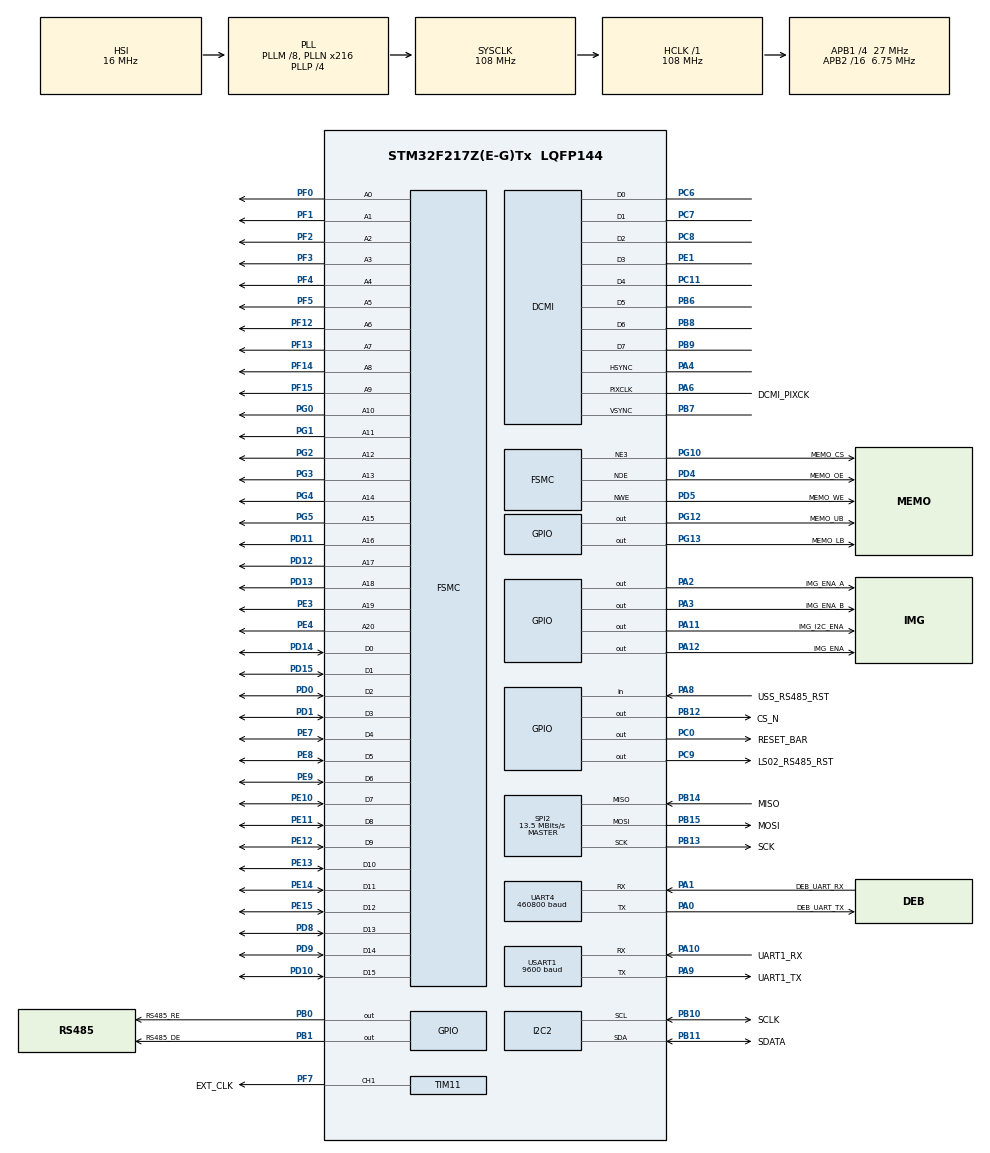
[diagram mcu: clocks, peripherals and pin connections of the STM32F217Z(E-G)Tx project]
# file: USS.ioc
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ADC1.Channel-1\#ChannelRegularConversion=ADC_CHANNEL_TEMPSENSOR
ADC1.Channel-2\#ChannelRegularConversion=ADC_CHANNEL_VREFINT
ADC1.InjNumberOfConversion=0
ADC1.NbrOfConversion=2
ADC1.NbrOfConversionFlag=1
ADC1.Rank-1\#ChannelRegularConversion=1
ADC1.Rank-2\#ChannelRegularConversion=2
ADC1.SamplingTime-1\#ChannelRegularConversion=ADC_SAMPLETIME_144CYCLES
ADC1.SamplingTime-2\#ChannelRegularConversion=ADC_SAMPLETIME_144CYCLES
ADC1.ScanConvMode=ENABLE
ADC1.master=1
DCMI.HSPolarity=DCMI_HSPOLARITY_LOW
DCMI.JPEGMode=DCMI_JPEG_DISABLE
DCMI.PCKPolarity=DCMI_PCKPOLARITY_RISING
DCMI.VSPolarity=DCMI_VSPOLARITY_LOW
Dma.DCMI.0.Direction=DMA_PERIPH_TO_MEMORY
Dma.DCMI.0.FIFOMode=DMA_FIFOMODE_ENABLE
Dma.DCMI.0.FIFOThreshold=DMA_FIFO_THRESHOLD_FULL
Dma.DCMI.0.Instance=DMA2_Stream1
Dma.DCMI.0.MemBurst=DMA_MBURST_INC4
Dma.DCMI.0.MemDataAlignment=DMA_MDATAALIGN_WORD
Dma.DCMI.0.MemInc=DMA_MINC_ENABLE
Dma.DCMI.0.Mode=DMA_NORMAL
Dma.DCMI.0.PeriphBurst=DMA_PBURST_SINGLE
Dma.DCMI.0.PeriphDataAlignment=DMA_PDATAALIGN_WORD
Dma.DCMI.0.PeriphInc=DMA_PINC_DISABLE
Dma.DCMI.0.Priority=DMA_PRIORITY_VERY_HIGH
Dma.Request0=DCMI
FSMC.AddressSetupTime1=0
FSMC.BusTurnAroundDuration1=1
FSMC.DataSetupTime1=3
FSMC.WriteOperation1=FSMC_WRITE_OPERATION_ENABLE
IWDG.Prescaler=IWDG_PRESCALER_64
Mcu.Family=STM32F2
Mcu.Name=STM32F217Z(E-G)Tx
Mcu.Package=LQFP144
NVIC.DCMI_IRQn=true\:1\:0\:true\:false\:true\:true\:true\:true
NVIC.DMA2_Stream1_IRQn=true\:1\:0\:true\:false\:true\:false\:true\:true
NVIC.PriorityGroup=NVIC_PRIORITYGROUP_4
NVIC.USART1_IRQn=true\:2\:0\:true\:false\:true\:true\:true\:true
PA0-WKUP.GPIO_Label=DEB_UART_TX
PA0-WKUP.Mode=Asynchronous
PA0-WKUP.Signal=UART4_TX
PA1.GPIO_Label=DEB_UART_RX
PA1.Mode=Asynchronous
PA1.Signal=UART4_RX
PA10.GPIO_Label=UART1_RX
PA10.Mode=Asynchronous
PA10.Signal=USART1_RX
PA11.GPIO_Label=IMG_I2C_ENA
PA11.PinState=GPIO_PIN_RESET
PA11.Signal=GPIO_Output
PA12.GPIO_Label=IMG_ENA
PA12.Signal=GPIO_Output
PA13.GPIO_Label=JTMS/SWDIO
PA13.Mode=Serial_Wire
PA13.Signal=SYS_JTMS-SWDIO
PA14.GPIO_Label=JTCK/SWCLK
PA14.Mode=Serial_Wire
PA14.Signal=SYS_JTCK-SWCLK
PA2.GPIO_Label=IMG_ENA_A
PA2.GPIO_PuPd=GPIO_NOPULL
PA2.GPIO_Speed=GPIO_SPEED_FREQ_LOW
PA2.Signal=GPIO_Output
PA3.GPIO_Label=IMG_ENA_B
PA3.GPIO_PuPd=GPIO_NOPULL
PA3.Signal=GPIO_Output
PA4.GPIO_Speed=GPIO_SPEED_FREQ_VERY_HIGH
PA4.Mode=Slave_8_bits_External_Synchro
PA4.Signal=DCMI_HSYNC
PA6.GPIO_Label=DCMI_PIXCK
PA6.GPIO_PuPd=GPIO_NOPULL
PA6.GPIO_Speed=GPIO_SPEED_FREQ_VERY_HIGH
PA6.Mode=Slave_8_bits_External_Synchro
PA6.Signal=DCMI_PIXCLK
PA8.GPIO_Label=USS_RS485_RST
PA8.GPIO_PuPd=GPIO_PULLUP
PA8.Signal=GPIO_Input
PA9.GPIO_Label=UART1_TX
PA9.Mode=Asynchronous
PA9.Signal=USART1_TX
PB0.GPIO_Label=RS485_RE
PB0.GPIO_Speed=GPIO_SPEED_FREQ_HIGH
PB0.PinState=GPIO_PIN_RESET
PB0.Signal=GPIO_Output
PB1.GPIO_Label=RS485_DE
PB1.GPIO_Speed=GPIO_SPEED_FREQ_HIGH
PB1.Signal=GPIO_Output
PB10.GPIO_Label=SCLK
PB10.Mode=I2C
PB10.Signal=I2C2_SCL
PB11.GPIO_Label=SDATA
PB11.Mode=I2C
PB11.Signal=I2C2_SDA
PB12.GPIO_Label=CS_N
PB12.PinState=GPIO_PIN_RESET
PB12.Signal=GPIO_Output
PB13.GPIO_Label=SCK
PB13.Mode=Full_Duplex_Master
PB13.Signal=SPI2_SCK
PB14.GPIO_Label=MISO
PB14.Mode=Full_Duplex_Master
PB14.Signal=SPI2_MISO
PB15.GPIO_Label=MOSI
PB15.Mode=Full_Duplex_Master
PB15.Signal=SPI2_MOSI
PB6.GPIO_Speed=GPIO_SPEED_FREQ_VERY_HIGH
PB6.Mode=Slave_8_bits_External_Synchro
PB6.Signal=DCMI_D5
PB7.GPIO_Speed=GPIO_SPEED_FREQ_VERY_HIGH
PB7.Mode=Slave_8_bits_External_Synchro
PB7.Signal=DCMI_VSYNC
PB8.GPIO_Speed=GPIO_SPEED_FREQ_VERY_HIGH
PB8.Mode=Slave_8_bits_External_Synchro
PB8.Signal=DCMI_D6
PB9.GPIO_Speed=GPIO_SPEED_FREQ_VERY_HIGH
PB9.Mode=Slave_8_bits_External_Synchro
PB9.Signal=DCMI_D7
PC0.GPIO_Label=RESET_BAR
PC0.PinState=GPIO_PIN_RESET
PC0.Signal=GPIO_Output
PC11.GPIO_Speed=GPIO_SPEED_FREQ_VERY_HIGH
PC11.Mode=Slave_8_bits_External_Synchro
PC11.Signal=DCMI_D4
PC14-OSC32_IN.Mode=LSE-External-Oscillator
PC14-OSC32_IN.Signal=RCC_OSC32_IN
PC15-OSC32_OUT.Mode=LSE-External-Oscillator
PC15-OSC32_OUT.Signal=RCC_OSC32_OUT
PC6.GPIO_Speed=GPIO_SPEED_FREQ_VERY_HIGH
PC6.Mode=Slave_8_bits_External_Synchro
PC6.Signal=DCMI_D0
PC7.GPIO_Speed=GPIO_SPEED_FREQ_VERY_HIGH
PC7.Mode=Slave_8_bits_External_Synchro
PC7.Signal=DCMI_D1
PC8.GPIO_Speed=GPIO_SPEED_FREQ_VERY_HIGH
PC8.Mode=Slave_8_bits_External_Synchro
PC8.Signal=DCMI_D2
PC9.GPIO_Label=LS02_RS485_RST
PC9.GPIO_ModeDefaultOutputPP=GPIO_MODE_OUTPUT_OD
PC9.GPIO_PuPd=GPIO_PULLUP
PC9.PinState=GPIO_PIN_SET
PC9.Signal=GPIO_Output
PD0.Signal=FSMC_D2_DA2
PD1.Signal=FSMC_D3_DA3
PD10.Signal=FSMC_D15_DA15
PD11.Signal=FSMC_A16_CLE
PD12.Signal=FSMC_A17_ALE
PD13.Signal=FSMC_A18
PD14.Signal=FSMC_D0_DA0
PD15.Signal=FSMC_D1_DA1
PD4.GPIO_Label=MEMO_OE
PD4.Signal=FSMC_NOE
PD5.GPIO_Label=MEMO_WE
PD5.Signal=FSMC_NWE
PD8.Signal=FSMC_D13_DA13
PD9.Signal=FSMC_D14_DA14
PE1.GPIO_Speed=GPIO_SPEED_FREQ_VERY_HIGH
PE1.Mode=Slave_8_bits_External_Synchro
PE1.Signal=DCMI_D3
PE10.Signal=FSMC_D7_DA7
PE11.Signal=FSMC_D8_DA8
PE12.Signal=FSMC_D9_DA9
PE13.Signal=FSMC_D10_DA10
PE14.Signal=FSMC_D11_DA11
PE15.Signal=FSMC_D12_DA12
PE3.Signal=FSMC_A19
PE4.Signal=FSMC_A20
PE7.Signal=FSMC_D4_DA4
PE8.Signal=FSMC_D5_DA5
PE9.Signal=FSMC_D6_DA6
PF0.Signal=FSMC_A0
PF1.Signal=FSMC_A1
PF12.Signal=FSMC_A6
PF13.Signal=FSMC_A7
PF14.Signal=FSMC_A8
PF15.Signal=FSMC_A9
PF2.Signal=FSMC_A2
PF3.Signal=FSMC_A3
PF4.Signal=FSMC_A4
PF5.Signal=FSMC_A5
PF7.GPIO_Label=EXT_CLK
PF7.GPIO_Speed=GPIO_SPEED_FREQ_VERY_HIGH
PF7.Signal=S_TIM11_CH1
PG0.Signal=FSMC_A10
PG1.Signal=FSMC_A11
PG10.GPIO_Label=MEMO_CS
PG10.Mode=NorPsramChipSelect3_1
PG10.Signal=FSMC_NE3
PG12.GPIO_Label=MEMO_UB
PG12.Signal=GPIO_Output
PG13.GPIO_Label=MEMO_LB
PG13.Signal=GPIO_Output
PG2.Signal=FSMC_A12
PG3.Signal=FSMC_A13
PG4.Signal=FSMC_A14
PG5.Signal=FSMC_A15
PH0-OSC_IN.Mode=HSE-External-Oscillator
PH0-OSC_IN.Signal=RCC_OSC_IN
PH1-OSC_OUT.Mode=HSE-External-Oscillator
PH1-OSC_OUT.Signal=RCC_OSC_OUT
ProjectManager.HeapSize=0x200
ProjectManager.StackSize=0x400
ProjectManager.TargetToolchain=STM32CubeIDE
RCC.48MHZClocksFreq_Value=108000000
RCC.AHBFreq_Value=108000000
RCC.APB1CLKDivider=RCC_HCLK_DIV4
RCC.APB1Freq_Value=27000000
RCC.APB1TimFreq_Value=54000000
RCC.APB2CLKDivider=RCC_HCLK_DIV16
RCC.APB2Freq_Value=6750000
RCC.APB2TimFreq_Value=13500000
RCC.CortexFreq_Value=108000000
RCC.HCLKFreq_Value=108000000
RCC.HSE_VALUE=8000000
RCC.HSI_VALUE=16000000
RCC.PLLM=8
RCC.PLLN=216
RCC.PLLP=RCC_PLLP_DIV4
RCC.SYSCLKFreq_VALUE=108000000
RCC.SYSCLKSource=RCC_SYSCLKSOURCE_PLLCLK
RCC.VCOOutputFreq_Value=432000000
SH.FSMC_A0.0=FSMC_A0,21b-a1
SH.FSMC_A1.0=FSMC_A1,21b-a1
SH.FSMC_A10.0=FSMC_A10,21b-a1
SH.FSMC_A11.0=FSMC_A11,21b-a1
SH.FSMC_A12.0=FSMC_A12,21b-a1
SH.FSMC_A13.0=FSMC_A13,21b-a1
SH.FSMC_A14.0=FSMC_A14,21b-a1
SH.FSMC_A15.0=FSMC_A15,21b-a1
SH.FSMC_A16_CLE.0=FSMC_A16,21b-a1
SH.FSMC_A17_ALE.0=FSMC_A17,21b-a1
SH.FSMC_A18.0=FSMC_A18,21b-a1
SH.FSMC_A19.0=FSMC_A19,21b-a1
SH.FSMC_A2.0=FSMC_A2,21b-a1
SH.FSMC_A20.0=FSMC_A20,21b-a1
SH.FSMC_A3.0=FSMC_A3,21b-a1
SH.FSMC_A4.0=FSMC_A4,21b-a1
SH.FSMC_A5.0=FSMC_A5,21b-a1
SH.FSMC_A6.0=FSMC_A6,21b-a1
SH.FSMC_A7.0=FSMC_A7,21b-a1
SH.FSMC_A8.0=FSMC_A8,21b-a1
SH.FSMC_A9.0=FSMC_A9,21b-a1
SH.FSMC_D0_DA0.0=FSMC_D0,16b-d1
SH.FSMC_D10_DA10.0=FSMC_D10,16b-d1
SH.FSMC_D11_DA11.0=FSMC_D11,16b-d1
SH.FSMC_D12_DA12.0=FSMC_D12,16b-d1
SH.FSMC_D13_DA13.0=FSMC_D13,16b-d1
SH.FSMC_D14_DA14.0=FSMC_D14,16b-d1
SH.FSMC_D15_DA15.0=FSMC_D15,16b-d1
SH.FSMC_D1_DA1.0=FSMC_D1,16b-d1
SH.FSMC_D2_DA2.0=FSMC_D2,16b-d1
SH.FSMC_D3_DA3.0=FSMC_D3,16b-d1
SH.FSMC_D4_DA4.0=FSMC_D4,16b-d1
SH.FSMC_D5_DA5.0=FSMC_D5,16b-d1
SH.FSMC_D6_DA6.0=FSMC_D6,16b-d1
SH.FSMC_D7_DA7.0=FSMC_D7,16b-d1
SH.FSMC_D8_DA8.0=FSMC_D8,16b-d1
SH.FSMC_D9_DA9.0=FSMC_D9,16b-d1
SH.FSMC_NOE.0=FSMC_NOE,Sram1
SH.FSMC_NWE.0=FSMC_NWE,Sram1
SH.S_TIM11_CH1.0=TIM11_CH1,PWM Generation1 CH1
SPI2.BaudRatePrescaler=SPI_BAUDRATEPRESCALER_2
SPI2.CalculateBaudRate=13.5 MBits/s
SPI2.Direction=SPI_DIRECTION_2LINES
SPI2.Mode=SPI_MODE_MASTER
SPI2.VirtualType=VM_MASTER
TIM11.Channel=TIM_CHANNEL_1
TIM11.Period=1
TIM11.Pulse=1
UART4.BaudRate=460800
UART4.VirtualMode=Asynchronous
USART1.BaudRate=9600
USART1.VirtualMode=VM_ASYNC
VP_ADC1_TempSens_Input.Mode=IN-TempSens
VP_ADC1_Vref_Input.Mode=IN-Vrefint
VP_IWDG_VS_IWDG.Mode=IWDG_Activate
VP_TIM11_VS_ClockSourceINT.Mode=Enable_Timer
board=custom

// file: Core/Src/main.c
/* USER CODE BEGIN Header */
/**
  ******************************************************************************
  * @file           : main.c
  * @brief          : Application entry point
  * 				  USS Core initialization and main loop
  ******************************************************************************
  * @author         : Lucas Finazzi <lfinazzi@unsam.edu.ar> (2026)
  *
  ******************************************************************************
  */
/* USER CODE END Header */
#include "main.h"

/* USER CODE BEGIN Includes */
#include "comms.h"
#include "status.h"
#include "fram.h"
#include "telemetry.h"
#include "sram.h"
#include "gpio.h"
#include "command.h"
#include "protection.h"
/* USER CODE END Includes */

ADC_HandleTypeDef hadc1;

DCMI_HandleTypeDef hdcmi;
DMA_HandleTypeDef hdma_dcmi;

I2C_HandleTypeDef hi2c2;

IWDG_HandleTypeDef hiwdg;

SPI_HandleTypeDef hspi2;

TIM_HandleTypeDef htim11;

UART_HandleTypeDef huart4;
UART_HandleTypeDef huart1;

SRAM_HandleTypeDef hsram1;

void SystemClock_Config(void);
static void MX_GPIO_Init(void);
static void MX_DMA_Init(void);
static void MX_UART4_Init(void);
static void MX_DCMI_Init(void);
static void MX_USART1_UART_Init(void);
static void MX_I2C2_Init(void);
static void MX_SPI2_Init(void);
static void MX_FSMC_Init(void);
static void MX_TIM11_Init(void);
static void MX_IWDG_Init(void);
static void MX_ADC1_Init(void);

int main(void)
{

  /* USER CODE BEGIN 1 */

  /* Relocate vector table to application base — Already done in SystemInit(), but no harm to leave this here */
  SCB->VTOR = 0x08004000UL;

  uint8_t ignore_flag = 0;					// Used to only transmit "Waiting for reset" in debug UART the first time you enter STATE_IGNORE
  uint32_t timeout_start = 0;
  uint32_t telemetry_save_counter = 0;		// Counter used to save telemtery to FRAM periodically
  /* USER CODE END 1 */

  /* MCU Configuration--------------------------------------------------------*/

  /* Reset of all peripherals, Initializes the Flash interface and the Systick. */
  HAL_Init();

  /* Configure the system clock */
  SystemClock_Config();

  /* USER CODE BEGIN SysInit */
  __enable_irq();
  /* USER CODE END SysInit */

  /* Initialize all configured peripherals */
  MX_GPIO_Init();
  MX_DMA_Init();
  MX_UART4_Init();
  MX_DCMI_Init();
  MX_USART1_UART_Init();
  MX_I2C2_Init();
  MX_SPI2_Init();
  MX_FSMC_Init();
  MX_TIM11_Init();
  MX_IWDG_Init();
  MX_ADC1_Init();
  /* USER CODE BEGIN 2 */

  // Prints boot SpaceSnap banner
  PrintBanner();

  HAL_UARTEx_ReceiveToIdle_IT(&huart1, (uint8_t*) rx_buffer, AIRMAC_SIZE+1);		// Arms UART1 for IT reception

  // Wait for next inits
  HAL_Delay(10);

  // Loads board status saved in FRAM
  LoadBoardStatusFRAM();
  board_status.uptime_total += board_status.uptime_session / 1000;					// Loads the previous uptime to the total_uptime variable

  // Need this two lines to persist boot status
  CommitBoardStatus();
  SaveBoardStatusFRAM();

  CheckResetCause();	// Checks last reset cause and loads it in board_status

  // Clear volatile variables in RAM. These do not persist across resets
  ResetVolatileStatus();

  GPIO_Init();																		// GPIO default config on startup

  // SRAM integrity test
  TestSRAM();

  // Prints Status with Log()
  LogBoardStatus();					// Logs current status to UART4 (debug)

  /* USER CODE END 2 */

  /* Infinite loop */
  /* USER CODE BEGIN WHILE */
  Log("---------------------------------------------------\r\n");
  while (1)
  {
	  HAL_IWDG_Refresh(&hiwdg); 													// Kick the IWDG once per loop
	  UpdateStatus();

	  switch (GetState()) {
		  case STATE_IDLE:
			  if(rx_flag){
				  HandleIncomingCommand(STATE_IGNORE);								// Waits for command reception and modifies state accordingly
				  // If USS command, go to STATE_EXECUTE_COMMAND
				  // If other subsystem command, go to STATE_IGNORE
			  }
			  break;

		  case STATE_IGNORE:		// TODO INTEGRATION: Test with LS02 hardware, select if we will use pulldowns or not for signaling GPIOs
			  if(ignore_flag == 0)													// Only transmit buffer first time this is executed
			  {
				  Log("Waiting for reset\r\n");										// Return for DEB-UART for user to know IGNORE was reached
				  DisableRS485();
				  timeout_start = HAL_GetTick();									// Register starting time
				  ignore_flag = 1;
			  }

			  // Waiting for HW reset from LS02 - Using non-blocking (no while) - or timeout
			  if(PollUSSReset() || (HAL_GetTick() - timeout_start >= (uint32_t)IGNORE_TIMEOUT_MAX)){    // GPIO reset high --> reactivate reception (or timeout)
				  Log("Leaving IGNORE mode.\r\n");
				  Log("---------------------------------------------------\r\n");
				  rx_flag = 0; 															// to avoid receiving something while blocked
				  SetState(STATE_IDLE);
				  ignore_flag = 0;
				  EnableListenRS485();
			  }
			  break;

		  case STATE_EXECUTE_COMMAND:
			  current_command_pointer = GetCommand(instr_number);					// Identifies command to execute
			  cmd_ret = ExecuteCommand(current_command_pointer, instr_opcode);		// Executes command with opcode

			  if (cmd_ret == CMD_SCHEDULED) {
				  SetState(STATE_DELAYED_PICTURE);
				  CommitBoardStatus();        		/* re-seal with the new state included */
				  SaveBoardStatusFRAM();      		/* persist STATE_DELAYED_PICTURE immediately, to never cancel capture on SEU */
			  }
			  else {
				  SetState(STATE_TRANSMIT_RESPONSE);
			  }
			  break;

		  // **************************************************************************************************************************************************
		  // Only the CMD_TakePictureDelayed() can make the program reach this state
		  case STATE_DELAYED_PICTURE:

			  // Time elapsed recovers even in the case of power off. All time waited upto power off is conserved
		      uint32_t current_ts_sec = board_status.uptime_total + board_status.uptime_session / 1000;
			  uint32_t delayed_sec = (uint32_t)board_status.delayed_intervals * MIN_INTERVAL * 60;

			  if(board_status.delayed_flag == 0)					// Only transmit buffer if instruction requested this boot session
			  {
				  TransmitBufferRS485();							// Return for OBC, indicating command scheduled if everything ok
				  board_status.delayed_flag = 1;
			  }

			  if (rx_flag) {										// Board is catching any incoming messages to cancel the delayed picture command
				  HandleIncomingCommand(STATE_DELAYED_PICTURE);		// If other subsystem receives a message, ignore but stay in STATE_DELAY_PICTURE
				  break;
			  }

			  else if (current_ts_sec - board_status.delayed_start >= delayed_sec)					// Has the delay passed?
			  {
				  current_command_pointer = GetCommand(CMD_TAKE_PICTURE_BURST_ID);					// CMD_TakePictureBurst()
				  cmd_ret = ExecuteCommand(current_command_pointer, board_status.last_opcode);		// uses non-volatile state to recover from power down

				  ResetLS02();									// Re-activates LS-02 for next incoming instruction

				  Log("Going IDLE...\r\n");
				  SetState(STATE_IDLE);							// No point in transmitting response, as satellite will not be over GS
				  board_status.delayed_flag = 0;				// Reset flag on state exit
			  }
			  break;
		  // **************************************************************************************************************************************************

		  case STATE_TRANSMIT_RESPONSE:
			  Log("Transmitting buffer\r\n");
			  Log("---------------------------------------------------\r\n");

			  if(current_command_pointer->has_return == HAS_RETURN)		// Command returns response
				  TransmitBufferRS485();								// Transmits tx_buffer and resets LS-02
			  else {
				  ClearTxBuffer();
				  ResetLS02();											// Resets LS-02 even if tx_buffer is not transmitted
			  }

			  SetState(STATE_IDLE);
			  break;

		  default:
			  SetState(STATE_IDLE);
			  break;
	}
    /* USER CODE END WHILE */

    /* USER CODE BEGIN 3 */

	// This saves telemetry once per second, which is a tradeoff between program memory and FRAM staleness in favor of decreased chance
	// of FRAM corruption due to unwanted POR when SaveBoardStatusFRAM() is running...
    telemetry_save_counter++;
    if (telemetry_save_counter >= TELEMETRY_LOOPS_TO_SAVE_TELEMETRY) {
	    SaveBoardStatusFRAM();   	// Periodic telemetry persist, can get away with ~1 s (mitigates FRAM corruption due to unwanted POR on write)
	    CommitBoardStatus();		// Calculates the CRC of board_status in program memory, protects before status is saved
	    CommitCompressionTable();    /* seal AFTER save, protects until next loop's save */
	    telemetry_save_counter = 0;
    }

  }
  /* USER CODE END 3 */
}

void SystemClock_Config(void)
{
  RCC_OscInitTypeDef RCC_OscInitStruct = {0};
  RCC_ClkInitTypeDef RCC_ClkInitStruct = {0};

  /** Initializes the RCC Oscillators according to the specified parameters
  * in the RCC_OscInitTypeDef structure.
  */
  RCC_OscInitStruct.OscillatorType = RCC_OSCILLATORTYPE_HSI|RCC_OSCILLATORTYPE_LSI;
  RCC_OscInitStruct.HSIState = RCC_HSI_ON;
  RCC_OscInitStruct.HSICalibrationValue = RCC_HSICALIBRATION_DEFAULT;
  RCC_OscInitStruct.LSIState = RCC_LSI_ON;
  RCC_OscInitStruct.PLL.PLLState = RCC_PLL_ON;
  RCC_OscInitStruct.PLL.PLLSource = RCC_PLLSOURCE_HSI;
  RCC_OscInitStruct.PLL.PLLM = 8;
  RCC_OscInitStruct.PLL.PLLN = 216;
  RCC_OscInitStruct.PLL.PLLP = RCC_PLLP_DIV4;
  RCC_OscInitStruct.PLL.PLLQ = 4;
  if (HAL_RCC_OscConfig(&RCC_OscInitStruct) != HAL_OK)
  {
    Error_Handler();
  }

  /** Initializes the CPU, AHB and APB buses clocks
  */
  RCC_ClkInitStruct.ClockType = RCC_CLOCKTYPE_HCLK|RCC_CLOCKTYPE_SYSCLK
                              |RCC_CLOCKTYPE_PCLK1|RCC_CLOCKTYPE_PCLK2;
  RCC_ClkInitStruct.SYSCLKSource = RCC_SYSCLKSOURCE_PLLCLK;
  RCC_ClkInitStruct.AHBCLKDivider = RCC_SYSCLK_DIV1;
  RCC_ClkInitStruct.APB1CLKDivider = RCC_HCLK_DIV4;
  RCC_ClkInitStruct.APB2CLKDivider = RCC_HCLK_DIV16;

  if (HAL_RCC_ClockConfig(&RCC_ClkInitStruct, FLASH_LATENCY_3) != HAL_OK)
  {
    Error_Handler();
  }
}

static void MX_ADC1_Init(void)
{

  ADC_ChannelConfTypeDef sConfig = {0};

  /** Configure the global features of the ADC (Clock, Resolution, Data Alignment and number of conversion)
  */
  hadc1.Instance = ADC1;
  hadc1.Init.ClockPrescaler = ADC_CLOCK_SYNC_PCLK_DIV2;
  hadc1.Init.Resolution = ADC_RESOLUTION_12B;
  hadc1.Init.ScanConvMode = ENABLE;
  hadc1.Init.ContinuousConvMode = DISABLE;
  hadc1.Init.DiscontinuousConvMode = DISABLE;
  hadc1.Init.ExternalTrigConvEdge = ADC_EXTERNALTRIGCONVEDGE_NONE;
  hadc1.Init.ExternalTrigConv = ADC_SOFTWARE_START;
  hadc1.Init.DataAlign = ADC_DATAALIGN_RIGHT;
  hadc1.Init.NbrOfConversion = 2;
  hadc1.Init.DMAContinuousRequests = DISABLE;
  hadc1.Init.EOCSelection = ADC_EOC_SINGLE_CONV;
  if (HAL_ADC_Init(&hadc1) != HAL_OK)
  {
    Error_Handler();
  }

  /** Configure for the selected ADC regular channel its corresponding rank in the sequencer and its sample time.
  */
  sConfig.Channel = ADC_CHANNEL_TEMPSENSOR;
  sConfig.Rank = 1;
  sConfig.SamplingTime = ADC_SAMPLETIME_144CYCLES;
  if (HAL_ADC_ConfigChannel(&hadc1, &sConfig) != HAL_OK)
  {
    Error_Handler();
  }

  /** Configure for the selected ADC regular channel its corresponding rank in the sequencer and its sample time.
  */
  sConfig.Channel = ADC_CHANNEL_VREFINT;
  sConfig.Rank = 2;
  if (HAL_ADC_ConfigChannel(&hadc1, &sConfig) != HAL_OK)
  {
    Error_Handler();
  }

}

static void MX_DCMI_Init(void)
{

  hdcmi.Instance = DCMI;
  hdcmi.Init.SynchroMode = DCMI_SYNCHRO_HARDWARE;
  hdcmi.Init.PCKPolarity = DCMI_PCKPOLARITY_RISING;
  hdcmi.Init.VSPolarity = DCMI_VSPOLARITY_LOW;
  hdcmi.Init.HSPolarity = DCMI_HSPOLARITY_LOW;
  hdcmi.Init.CaptureRate = DCMI_CR_ALL_FRAME;
  hdcmi.Init.ExtendedDataMode = DCMI_EXTEND_DATA_8B;
  hdcmi.Init.JPEGMode = DCMI_JPEG_DISABLE;
  if (HAL_DCMI_Init(&hdcmi) != HAL_OK)
  {
    Error_Handler();
  }

}

static void MX_I2C2_Init(void)
{

  hi2c2.Instance = I2C2;
  hi2c2.Init.ClockSpeed = 100000;
  hi2c2.Init.DutyCycle = I2C_DUTYCYCLE_2;
  hi2c2.Init.OwnAddress1 = 0;
  hi2c2.Init.AddressingMode = I2C_ADDRESSINGMODE_7BIT;
  hi2c2.Init.DualAddressMode = I2C_DUALADDRESS_DISABLE;
  hi2c2.Init.OwnAddress2 = 0;
  hi2c2.Init.GeneralCallMode = I2C_GENERALCALL_DISABLE;
  hi2c2.Init.NoStretchMode = I2C_NOSTRETCH_DISABLE;
  if (HAL_I2C_Init(&hi2c2) != HAL_OK)
  {
    Error_Handler();
  }

}

static void MX_IWDG_Init(void)
{

  hiwdg.Instance = IWDG;
  hiwdg.Init.Prescaler = IWDG_PRESCALER_64;
  hiwdg.Init.Reload = 4095;
  if (HAL_IWDG_Init(&hiwdg) != HAL_OK)
  {
    Error_Handler();
  }

}

static void MX_SPI2_Init(void)
{

  /* SPI2 parameter configuration*/
  hspi2.Instance = SPI2;
  hspi2.Init.Mode = SPI_MODE_MASTER;
  hspi2.Init.Direction = SPI_DIRECTION_2LINES;
  hspi2.Init.DataSize = SPI_DATASIZE_8BIT;
  hspi2.Init.CLKPolarity = SPI_POLARITY_LOW;
  hspi2.Init.CLKPhase = SPI_PHASE_1EDGE;
  hspi2.Init.NSS = SPI_NSS_SOFT;
  hspi2.Init.BaudRatePrescaler = SPI_BAUDRATEPRESCALER_2;
  hspi2.Init.FirstBit = SPI_FIRSTBIT_MSB;
  hspi2.Init.TIMode = SPI_TIMODE_DISABLE;
  hspi2.Init.CRCCalculation = SPI_CRCCALCULATION_DISABLE;
  hspi2.Init.CRCPolynomial = 10;
  if (HAL_SPI_Init(&hspi2) != HAL_OK)
  {
    Error_Handler();
  }

}

static void MX_TIM11_Init(void)
{

  TIM_OC_InitTypeDef sConfigOC = {0};

  htim11.Instance = TIM11;
  htim11.Init.Prescaler = 0;
  htim11.Init.CounterMode = TIM_COUNTERMODE_UP;
  htim11.Init.Period = 1;
  htim11.Init.ClockDivision = TIM_CLOCKDIVISION_DIV1;
  htim11.Init.AutoReloadPreload = TIM_AUTORELOAD_PRELOAD_DISABLE;
  if (HAL_TIM_Base_Init(&htim11) != HAL_OK)
  {
    Error_Handler();
  }
  if (HAL_TIM_PWM_Init(&htim11) != HAL_OK)
  {
    Error_Handler();
  }
  sConfigOC.OCMode = TIM_OCMODE_PWM1;
  sConfigOC.Pulse = 1;
  sConfigOC.OCPolarity = TIM_OCPOLARITY_HIGH;
  sConfigOC.OCFastMode = TIM_OCFAST_DISABLE;
  if (HAL_TIM_PWM_ConfigChannel(&htim11, &sConfigOC, TIM_CHANNEL_1) != HAL_OK)
  {
    Error_Handler();
  }
  HAL_TIM_MspPostInit(&htim11);

}

static void MX_UART4_Init(void)
{

  huart4.Instance = UART4;
  huart4.Init.BaudRate = 460800;
  huart4.Init.WordLength = UART_WORDLENGTH_8B;
  huart4.Init.StopBits = UART_STOPBITS_1;
  huart4.Init.Parity = UART_PARITY_NONE;
  huart4.Init.Mode = UART_MODE_TX_RX;
  huart4.Init.HwFlowCtl = UART_HWCONTROL_NONE;
  huart4.Init.OverSampling = UART_OVERSAMPLING_16;
  if (HAL_UART_Init(&huart4) != HAL_OK)
  {
    Error_Handler();
  }

}

static void MX_USART1_UART_Init(void)
{

  huart1.Instance = USART1;
  huart1.Init.BaudRate = 9600;
  huart1.Init.WordLength = UART_WORDLENGTH_8B;
  huart1.Init.StopBits = UART_STOPBITS_1;
  huart1.Init.Parity = UART_PARITY_NONE;
  huart1.Init.Mode = UART_MODE_TX_RX;
  huart1.Init.HwFlowCtl = UART_HWCONTROL_NONE;
  huart1.Init.OverSampling = UART_OVERSAMPLING_16;
  if (HAL_UART_Init(&huart1) != HAL_OK)
  {
    Error_Handler();
  }

}

static void MX_DMA_Init(void)
{

  /* DMA controller clock enable */
  __HAL_RCC_DMA2_CLK_ENABLE();

  /* DMA interrupt init */
  /* DMA2_Stream1_IRQn interrupt configuration */
  HAL_NVIC_SetPriority(DMA2_Stream1_IRQn, 1, 0);
  HAL_NVIC_EnableIRQ(DMA2_Stream1_IRQn);

}

static void MX_GPIO_Init(void)
{
  GPIO_InitTypeDef GPIO_InitStruct = {0};

  /* GPIO Ports Clock Enable */
  __HAL_RCC_GPIOE_CLK_ENABLE();
  __HAL_RCC_GPIOC_CLK_ENABLE();
  __HAL_RCC_GPIOF_CLK_ENABLE();
  __HAL_RCC_GPIOH_CLK_ENABLE();
  __HAL_RCC_GPIOA_CLK_ENABLE();
  __HAL_RCC_GPIOB_CLK_ENABLE();
  __HAL_RCC_GPIOG_CLK_ENABLE();
  __HAL_RCC_GPIOD_CLK_ENABLE();

  /*Configure GPIO pin Output Level */
  HAL_GPIO_WritePin(RESET_BAR_GPIO_Port, RESET_BAR_Pin, GPIO_PIN_RESET);

  /*Configure GPIO pin Output Level */
  HAL_GPIO_WritePin(GPIOA, IMG_ENA_A_Pin|IMG_ENA_B_Pin|IMG_I2C_ENA_Pin|IMG_ENA_Pin, GPIO_PIN_RESET);

  /*Configure GPIO pin Output Level */
  HAL_GPIO_WritePin(GPIOB, RS485_RE_Pin|RS485_DE_Pin|CS_N_Pin, GPIO_PIN_RESET);

  /*Configure GPIO pin Output Level */
  HAL_GPIO_WritePin(LS02_RS485_RST_GPIO_Port, LS02_RS485_RST_Pin, GPIO_PIN_SET);

  /*Configure GPIO pin Output Level */
  HAL_GPIO_WritePin(GPIOG, MEMO_UB_Pin|MEMO_LB_Pin, GPIO_PIN_RESET);

  /*Configure GPIO pin : RESET_BAR_Pin */
  GPIO_InitStruct.Pin = RESET_BAR_Pin;
  GPIO_InitStruct.Mode = GPIO_MODE_OUTPUT_PP;
  GPIO_InitStruct.Pull = GPIO_NOPULL;
  GPIO_InitStruct.Speed = GPIO_SPEED_FREQ_LOW;
  HAL_GPIO_Init(RESET_BAR_GPIO_Port, &GPIO_InitStruct);

  /*Configure GPIO pins : IMG_ENA_A_Pin IMG_ENA_B_Pin IMG_I2C_ENA_Pin IMG_ENA_Pin */
  GPIO_InitStruct.Pin = IMG_ENA_A_Pin|IMG_ENA_B_Pin|IMG_I2C_ENA_Pin|IMG_ENA_Pin;
  GPIO_InitStruct.Mode = GPIO_MODE_OUTPUT_PP;
  GPIO_InitStruct.Pull = GPIO_NOPULL;
  GPIO_InitStruct.Speed = GPIO_SPEED_FREQ_LOW;
  HAL_GPIO_Init(GPIOA, &GPIO_InitStruct);

  /*Configure GPIO pins : RS485_RE_Pin RS485_DE_Pin */
  GPIO_InitStruct.Pin = RS485_RE_Pin|RS485_DE_Pin;
  GPIO_InitStruct.Mode = GPIO_MODE_OUTPUT_PP;
  GPIO_InitStruct.Pull = GPIO_NOPULL;
  GPIO_InitStruct.Speed = GPIO_SPEED_FREQ_HIGH;
  HAL_GPIO_Init(GPIOB, &GPIO_InitStruct);

  /*Configure GPIO pin : CS_N_Pin */
  GPIO_InitStruct.Pin = CS_N_Pin;
  GPIO_InitStruct.Mode = GPIO_MODE_OUTPUT_PP;
  GPIO_InitStruct.Pull = GPIO_NOPULL;
  GPIO_InitStruct.Speed = GPIO_SPEED_FREQ_LOW;
  HAL_GPIO_Init(CS_N_GPIO_Port, &GPIO_InitStruct);

  /*Configure GPIO pin : LS02_RS485_RST_Pin */
  GPIO_InitStruct.Pin = LS02_RS485_RST_Pin;
  GPIO_InitStruct.Mode = GPIO_MODE_OUTPUT_OD;
  GPIO_InitStruct.Pull = GPIO_PULLUP;
  GPIO_InitStruct.Speed = GPIO_SPEED_FREQ_LOW;
  HAL_GPIO_Init(LS02_RS485_RST_GPIO_Port, &GPIO_InitStruct);

  /*Configure GPIO pin : USS_RS485_RST_Pin */
  GPIO_InitStruct.Pin = USS_RS485_RST_Pin;
  GPIO_InitStruct.Mode = GPIO_MODE_INPUT;
  GPIO_InitStruct.Pull = GPIO_PULLUP;
  HAL_GPIO_Init(USS_RS485_RST_GPIO_Port, &GPIO_InitStruct);

  /*Configure GPIO pins : MEMO_UB_Pin MEMO_LB_Pin */
  GPIO_InitStruct.Pin = MEMO_UB_Pin|MEMO_LB_Pin;
  GPIO_InitStruct.Mode = GPIO_MODE_OUTPUT_PP;
  GPIO_InitStruct.Pull = GPIO_NOPULL;
  GPIO_InitStruct.Speed = GPIO_SPEED_FREQ_LOW;
  HAL_GPIO_Init(GPIOG, &GPIO_InitStruct);

}

/* FSMC initialization function */
static void MX_FSMC_Init(void)
{

  FSMC_NORSRAM_TimingTypeDef Timing = {0};

  /** Perform the SRAM1 memory initialization sequence
  */
  hsram1.Instance = FSMC_NORSRAM_DEVICE;
  hsram1.Extended = FSMC_NORSRAM_EXTENDED_DEVICE;
  /* hsram1.Init */
  hsram1.Init.NSBank = FSMC_NORSRAM_BANK3;
  hsram1.Init.DataAddressMux = FSMC_DATA_ADDRESS_MUX_DISABLE;
  hsram1.Init.MemoryType = FSMC_MEMORY_TYPE_SRAM;
  hsram1.Init.MemoryDataWidth = FSMC_NORSRAM_MEM_BUS_WIDTH_16;
  hsram1.Init.BurstAccessMode = FSMC_BURST_ACCESS_MODE_DISABLE;
  hsram1.Init.WaitSignalPolarity = FSMC_WAIT_SIGNAL_POLARITY_LOW;
  hsram1.Init.WrapMode = FSMC_WRAP_MODE_DISABLE;
  hsram1.Init.WaitSignalActive = FSMC_WAIT_TIMING_BEFORE_WS;
  hsram1.Init.WriteOperation = FSMC_WRITE_OPERATION_ENABLE;
  hsram1.Init.WaitSignal = FSMC_WAIT_SIGNAL_DISABLE;
  hsram1.Init.ExtendedMode = FSMC_EXTENDED_MODE_DISABLE;
  hsram1.Init.AsynchronousWait = FSMC_ASYNCHRONOUS_WAIT_DISABLE;
  hsram1.Init.WriteBurst = FSMC_WRITE_BURST_DISABLE;
  /* Timing */
  Timing.AddressSetupTime = 0;
  Timing.AddressHoldTime = 15;
  Timing.DataSetupTime = 3;
  Timing.BusTurnAroundDuration = 1;
  Timing.CLKDivision = 16;
  Timing.DataLatency = 17;
  Timing.AccessMode = FSMC_ACCESS_MODE_A;
  /* ExtTiming */

  if (HAL_SRAM_Init(&hsram1, &Timing, NULL) != HAL_OK)
  {
    Error_Handler( );
  }

}

void Error_Handler(void)
{
  __disable_irq();
  while (1)
  {
  }
}
